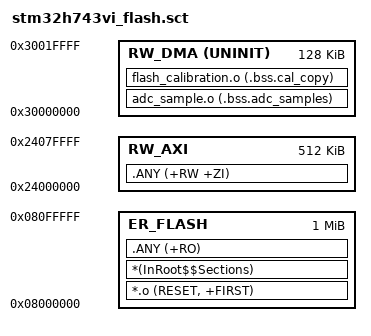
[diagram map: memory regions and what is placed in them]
; 程序位于 Bank 1，开短路校准占 Bank 2 的两个独立扇区。
; .bss.adc_samples 和 .bss.cal_copy 由 DMA 使用，放在 D2 SRAM1。
LR_FLASH 0x08000000 0x00100000
{
    ER_FLASH 0x08000000 0x00100000
    {
        *.o (RESET, +FIRST)
        *(InRoot$$Sections)
        .ANY (+RO)
    }
    RW_DMA 0x30000000 UNINIT 0x00020000
    {
        adc_sample.o (.bss.adc_samples)
        flash_calibration.o (.bss.cal_copy)
    }
    RW_AXI 0x24000000 0x00080000
    {
        .ANY (+RW +ZI)
    }
}
